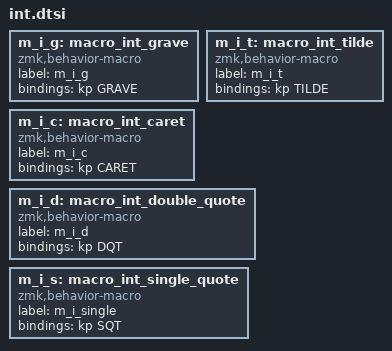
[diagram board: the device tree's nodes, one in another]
// tap:     `
m_i_g: macro_int_grave {
    compatible = "zmk,behavior-macro";
    label = "m_i_g";
    #binding-cells = <0>;
    bindings =
        <&kp GRAVE>;
};

// tap:     ~
m_i_t: macro_int_tilde {
    compatible = "zmk,behavior-macro";
    label = "m_i_t";
    #binding-cells = <0>;
    bindings =
        <&kp TILDE>;
};

// tap:     ^
m_i_c: macro_int_caret {
    compatible = "zmk,behavior-macro";
    label = "m_i_c";
    #binding-cells = <0>;
    bindings =
        <&kp CARET>;
};

// tap:     "
m_i_d: macro_int_double_quote {
    compatible = "zmk,behavior-macro";
    label = "m_i_d";
    #binding-cells = <0>;
    bindings =
        <&kp DQT>;
};

// tap:     '
m_i_s: macro_int_single_quote {
    compatible = "zmk,behavior-macro";
    label = "m_i_single";
    #binding-cells = <0>;
    bindings =
        <&kp SQT>;
};
